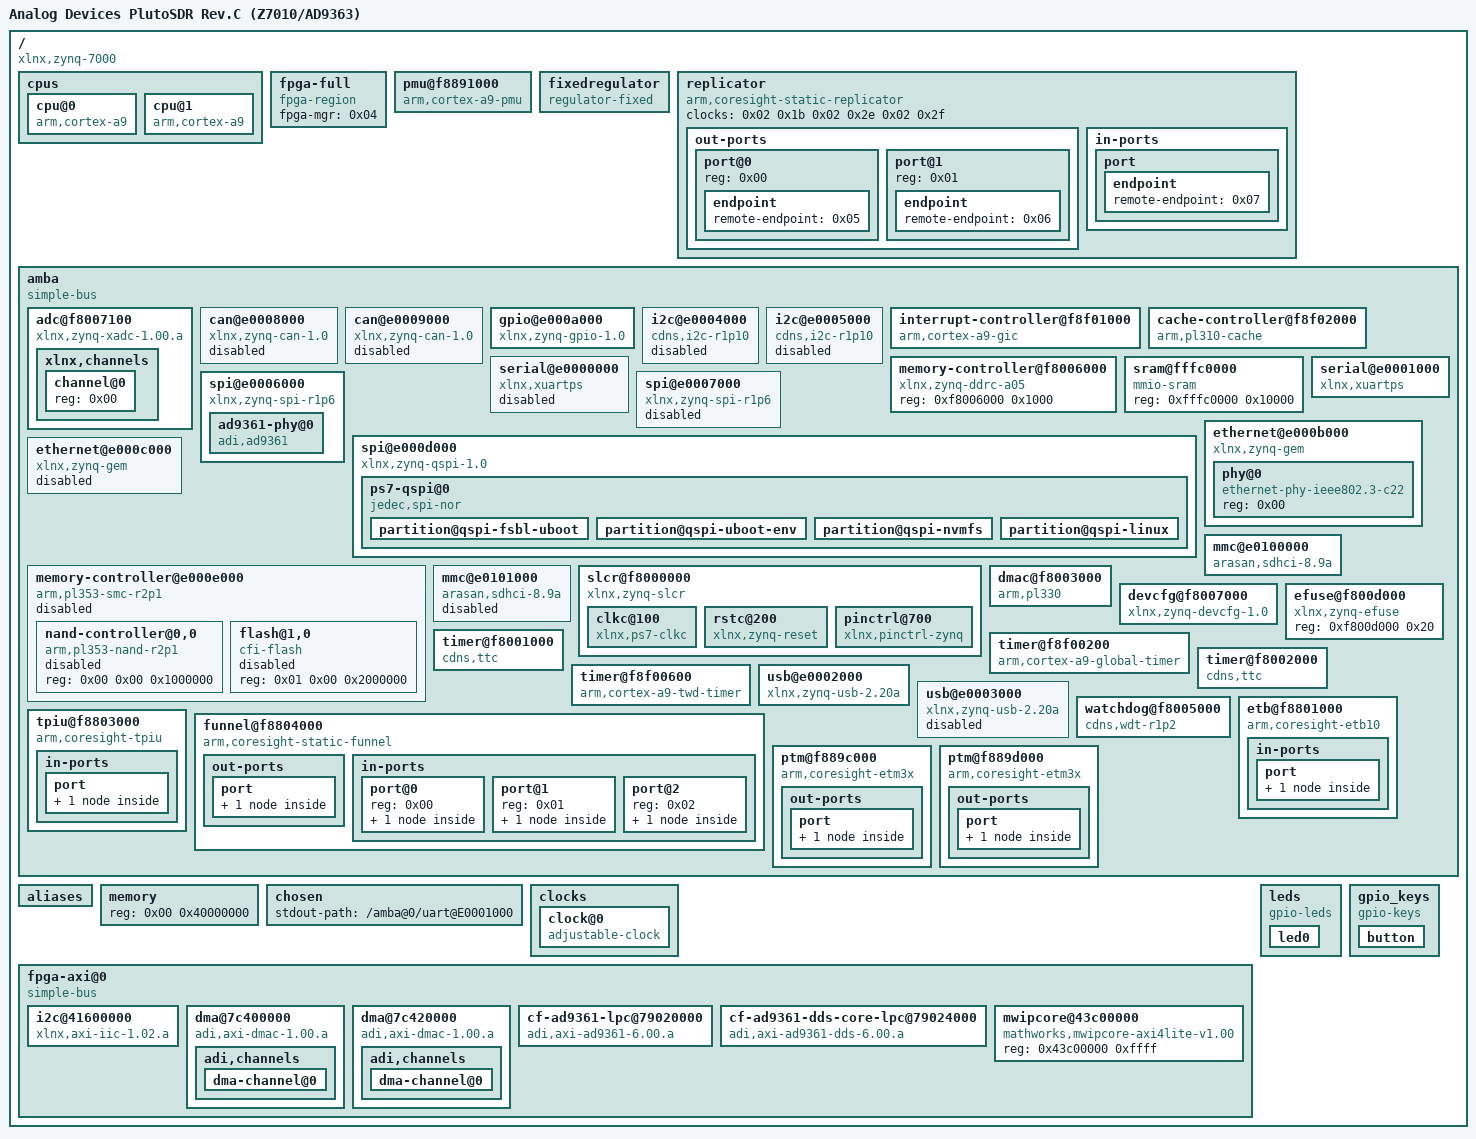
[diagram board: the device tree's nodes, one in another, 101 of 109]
/dts-v1/;

/ {
	#address-cells = <0x01>;
	#size-cells = <0x01>;
	compatible = "xlnx,zynq-7000";
	interrupt-parent = <0x01>;
	model = "Analog Devices PlutoSDR Rev.C (Z7010/AD9363)";

	cpus {
		#address-cells = <0x01>;
		#size-cells = <0x00>;

		cpu@0 {
			compatible = "arm,cortex-a9";
			device_type = "cpu";
			reg = <0x00>;
			clocks = <0x02 0x03>;
			clock-latency = <0x3e8>;
			cpu0-supply = <0x03>;
			operating-points = <0xa2c2b 0xf4240 0x51616 0xf4240>;
			phandle = <0x11>;
		};

		cpu@1 {
			compatible = "arm,cortex-a9";
			device_type = "cpu";
			reg = <0x01>;
			clocks = <0x02 0x03>;
			phandle = <0x13>;
		};
	};

	fpga-full {
		compatible = "fpga-region";
		fpga-mgr = <0x04>;
		#address-cells = <0x01>;
		#size-cells = <0x01>;
		ranges;
		phandle = <0x18>;
	};

	pmu@f8891000 {
		compatible = "arm,cortex-a9-pmu";
		interrupts = <0x00 0x05 0x04 0x00 0x06 0x04>;
		interrupt-parent = <0x01>;
		reg = <0xf8891000 0x1000 0xf8893000 0x1000>;
	};

	fixedregulator {
		compatible = "regulator-fixed";
		regulator-name = "VCCPINT";
		regulator-min-microvolt = <0xf4240>;
		regulator-max-microvolt = <0xf4240>;
		regulator-boot-on;
		regulator-always-on;
		phandle = <0x03>;
	};

	replicator {
		compatible = "arm,coresight-static-replicator";
		clocks = <0x02 0x1b 0x02 0x2e 0x02 0x2f>;
		clock-names = "apb_pclk\0dbg_trc\0dbg_apb";

		out-ports {
			#address-cells = <0x01>;
			#size-cells = <0x00>;

			port@0 {
				reg = <0x00>;

				endpoint {
					remote-endpoint = <0x05>;
					phandle = <0x0d>;
				};
			};

			port@1 {
				reg = <0x01>;

				endpoint {
					remote-endpoint = <0x06>;
					phandle = <0x0c>;
				};
			};
		};

		in-ports {

			port {

				endpoint {
					remote-endpoint = <0x07>;
					phandle = <0x0e>;
				};
			};
		};
	};

	amba {
		u-boot,dm-pre-reloc;
		compatible = "simple-bus";
		#address-cells = <0x01>;
		#size-cells = <0x01>;
		interrupt-parent = <0x01>;
		ranges;
		phandle = <0x19>;

		adc@f8007100 {
			compatible = "xlnx,zynq-xadc-1.00.a";
			reg = <0xf8007100 0x20>;
			interrupts = <0x00 0x07 0x04>;
			interrupt-parent = <0x01>;
			clocks = <0x02 0x0c>;
			phandle = <0x1a>;

			xlnx,channels {
				#address-cells = <0x01>;
				#size-cells = <0x00>;

				channel@0 {
					reg = <0x00>;
				};
			};
		};

		can@e0008000 {
			compatible = "xlnx,zynq-can-1.0";
			status = "disabled";
			clocks = <0x02 0x13 0x02 0x24>;
			clock-names = "can_clk\0pclk";
			reg = <0xe0008000 0x1000>;
			interrupts = <0x00 0x1c 0x04>;
			interrupt-parent = <0x01>;
			tx-fifo-depth = <0x40>;
			rx-fifo-depth = <0x40>;
			phandle = <0x1b>;
		};

		can@e0009000 {
			compatible = "xlnx,zynq-can-1.0";
			status = "disabled";
			clocks = <0x02 0x14 0x02 0x25>;
			clock-names = "can_clk\0pclk";
			reg = <0xe0009000 0x1000>;
			interrupts = <0x00 0x33 0x04>;
			interrupt-parent = <0x01>;
			tx-fifo-depth = <0x40>;
			rx-fifo-depth = <0x40>;
			phandle = <0x1c>;
		};

		gpio@e000a000 {
			compatible = "xlnx,zynq-gpio-1.0";
			#gpio-cells = <0x02>;
			clocks = <0x02 0x2a>;
			gpio-controller;
			interrupt-controller;
			#interrupt-cells = <0x02>;
			interrupt-parent = <0x01>;
			interrupts = <0x00 0x14 0x04>;
			reg = <0xe000a000 0x1000>;
			phandle = <0x09>;
		};

		i2c@e0004000 {
			compatible = "cdns,i2c-r1p10";
			status = "disabled";
			clocks = <0x02 0x26>;
			interrupt-parent = <0x01>;
			interrupts = <0x00 0x19 0x04>;
			reg = <0xe0004000 0x1000>;
			#address-cells = <0x01>;
			#size-cells = <0x00>;
			phandle = <0x1d>;
		};

		i2c@e0005000 {
			compatible = "cdns,i2c-r1p10";
			status = "disabled";
			clocks = <0x02 0x27>;
			interrupt-parent = <0x01>;
			interrupts = <0x00 0x30 0x04>;
			reg = <0xe0005000 0x1000>;
			#address-cells = <0x01>;
			#size-cells = <0x00>;
			phandle = <0x1e>;
		};

		interrupt-controller@f8f01000 {
			compatible = "arm,cortex-a9-gic";
			#interrupt-cells = <0x03>;
			interrupt-controller;
			reg = <0xf8f01000 0x1000 0xf8f00100 0x100>;
			phandle = <0x01>;
		};

		cache-controller@f8f02000 {
			compatible = "arm,pl310-cache";
			reg = <0xf8f02000 0x1000>;
			interrupts = <0x00 0x02 0x04>;
			arm,data-latency = <0x03 0x02 0x02>;
			arm,tag-latency = <0x02 0x02 0x02>;
			cache-unified;
			cache-level = <0x02>;
			phandle = <0x1f>;
		};

		memory-controller@f8006000 {
			compatible = "xlnx,zynq-ddrc-a05";
			reg = <0xf8006000 0x1000>;
			phandle = <0x20>;
		};

		sram@fffc0000 {
			compatible = "mmio-sram";
			reg = <0xfffc0000 0x10000>;
			phandle = <0x21>;
		};

		serial@e0000000 {
			compatible = "xlnx,xuartps\0cdns,uart-r1p8";
			status = "disabled";
			clocks = <0x02 0x17 0x02 0x28>;
			clock-names = "uart_clk\0pclk";
			reg = <0xe0000000 0x1000>;
			interrupts = <0x00 0x1b 0x04>;
			phandle = <0x22>;
		};

		serial@e0001000 {
			compatible = "xlnx,xuartps\0cdns,uart-r1p8";
			status = "okay";
			clocks = <0x02 0x18 0x02 0x29>;
			clock-names = "uart_clk\0pclk";
			reg = <0xe0001000 0x1000>;
			interrupts = <0x00 0x32 0x04>;
			phandle = <0x23>;
		};

		spi@e0006000 {
			compatible = "xlnx,zynq-spi-r1p6";
			reg = <0xe0006000 0x1000>;
			status = "okay";
			interrupt-parent = <0x01>;
			interrupts = <0x00 0x1a 0x04>;
			clocks = <0x02 0x19 0x02 0x22>;
			clock-names = "ref_clk\0pclk";
			#address-cells = <0x01>;
			#size-cells = <0x00>;
			phandle = <0x24>;

			ad9361-phy@0 {
				#address-cells = <0x01>;
				#size-cells = <0x00>;
				#clock-cells = <0x01>;
				compatible = "adi,ad9361";
				reg = <0x00>;
				spi-cpha;
				spi-max-frequency = <0x989680>;
				clocks = <0x08 0x00>;
				clock-names = "ad9364_ext_refclk";
				clock-output-names = "rx_sampl_clk\0tx_sampl_clk";
				adi,digital-interface-tune-skip-mode = <0x00>;
				adi,pp-tx-swap-enable;
				adi,pp-rx-swap-enable;
				adi,rx-frame-pulse-mode-enable;
				adi,lvds-mode-enable;
				adi,lvds-bias-mV = <0x96>;
				adi,lvds-rx-onchip-termination-enable;
				adi,rx-data-delay = <0x04>;
				adi,tx-fb-clock-delay = <0x07>;
				adi,tx-data-delay = <0x09>;
				adi,xo-disable-use-ext-refclk-enable;
				adi,frequency-division-duplex-mode-enable;
				adi,rx-rf-port-input-select = <0x00>;
				adi,rx-rf-port-input-select-lock-enable;
				adi,tx-rf-port-input-select = <0x00>;
				adi,tx-rf-port-input-select-lock-enable;
				adi,tx-attenuation-mdB = <0x2710>;
				adi,tx-lo-powerdown-managed-enable;
				adi,rf-rx-bandwidth-hz = <0x112a880>;
				adi,rf-tx-bandwidth-hz = <0x112a880>;
				adi,rx-synthesizer-frequency-hz = <0x00 0x8f0d1800>;
				adi,tx-synthesizer-frequency-hz = <0x00 0x8f0d1800>;
				adi,rx-path-clock-frequencies = <0x3a980000 0xea60000 0x7530000 0x3a98000 0x1d4c000 0x1d4c000>;
				adi,tx-path-clock-frequencies = <0x3a980000 0x7530000 0x7530000 0x3a98000 0x1d4c000 0x1d4c000>;
				adi,gc-rx1-mode = <0x02>;
				adi,gc-rx2-mode = <0x02>;
				adi,gc-adc-ovr-sample-size = <0x04>;
				adi,gc-adc-small-overload-thresh = <0x2f>;
				adi,gc-adc-large-overload-thresh = <0x3a>;
				adi,gc-lmt-overload-high-thresh = <0x320>;
				adi,gc-lmt-overload-low-thresh = <0x2c0>;
				adi,gc-dec-pow-measurement-duration = <0x2000>;
				adi,gc-low-power-thresh = <0x18>;
				adi,mgc-inc-gain-step = <0x02>;
				adi,mgc-dec-gain-step = <0x02>;
				adi,mgc-split-table-ctrl-inp-gain-mode = <0x00>;
				adi,agc-attack-delay-extra-margin-us = <0x01>;
				adi,agc-outer-thresh-high = <0x05>;
				adi,agc-outer-thresh-high-dec-steps = <0x02>;
				adi,agc-inner-thresh-high = <0x0a>;
				adi,agc-inner-thresh-high-dec-steps = <0x01>;
				adi,agc-inner-thresh-low = <0x0c>;
				adi,agc-inner-thresh-low-inc-steps = <0x01>;
				adi,agc-outer-thresh-low = <0x12>;
				adi,agc-outer-thresh-low-inc-steps = <0x02>;
				adi,agc-adc-small-overload-exceed-counter = <0x0a>;
				adi,agc-adc-large-overload-exceed-counter = <0x0a>;
				adi,agc-adc-large-overload-inc-steps = <0x02>;
				adi,agc-lmt-overload-large-exceed-counter = <0x0a>;
				adi,agc-lmt-overload-small-exceed-counter = <0x0a>;
				adi,agc-lmt-overload-large-inc-steps = <0x02>;
				adi,agc-gain-update-interval-us = <0x3e8>;
				adi,fagc-dec-pow-measurement-duration = <0x40>;
				adi,fagc-lp-thresh-increment-steps = <0x01>;
				adi,fagc-lp-thresh-increment-time = <0x05>;
				adi,fagc-energy-lost-stronger-sig-gain-lock-exit-cnt = <0x08>;
				adi,fagc-final-overrange-count = <0x03>;
				adi,fagc-gain-index-type-after-exit-rx-mode = <0x00>;
				adi,fagc-lmt-final-settling-steps = <0x01>;
				adi,fagc-lock-level = <0x0a>;
				adi,fagc-lock-level-gain-increase-upper-limit = <0x05>;
				adi,fagc-lock-level-lmt-gain-increase-enable;
				adi,fagc-lpf-final-settling-steps = <0x01>;
				adi,fagc-optimized-gain-offset = <0x05>;
				adi,fagc-power-measurement-duration-in-state5 = <0x40>;
				adi,fagc-rst-gla-engergy-lost-goto-optim-gain-enable;
				adi,fagc-rst-gla-engergy-lost-sig-thresh-below-ll = <0x0a>;
				adi,fagc-rst-gla-engergy-lost-sig-thresh-exceeded-enable;
				adi,fagc-rst-gla-if-en-agc-pulled-high-mode = <0x00>;
				adi,fagc-rst-gla-large-adc-overload-enable;
				adi,fagc-rst-gla-large-lmt-overload-enable;
				adi,fagc-rst-gla-stronger-sig-thresh-above-ll = <0x0a>;
				adi,fagc-rst-gla-stronger-sig-thresh-exceeded-enable;
				adi,fagc-state-wait-time-ns = <0x104>;
				adi,fagc-use-last-lock-level-for-set-gain-enable;
				adi,rssi-restart-mode = <0x03>;
				adi,rssi-delay = <0x01>;
				adi,rssi-wait = <0x01>;
				adi,rssi-duration = <0x3e8>;
				adi,ctrl-outs-index = <0x00>;
				adi,ctrl-outs-enable-mask = <0xff>;
				adi,temp-sense-measurement-interval-ms = <0x3e8>;
				adi,temp-sense-offset-signed = <0xce>;
				adi,temp-sense-periodic-measurement-enable;
				adi,aux-dac-manual-mode-enable;
				adi,aux-dac1-default-value-mV = <0x00>;
				adi,aux-dac1-rx-delay-us = <0x00>;
				adi,aux-dac1-tx-delay-us = <0x00>;
				adi,aux-dac2-default-value-mV = <0x00>;
				adi,aux-dac2-rx-delay-us = <0x00>;
				adi,aux-dac2-tx-delay-us = <0x00>;
				en_agc-gpios = <0x09 0x42 0x00>;
				reset-gpios = <0x09 0x43 0x00>;
				adi,2rx-2tx-mode-enable;
				phandle = <0x16>;
			};
		};

		spi@e0007000 {
			compatible = "xlnx,zynq-spi-r1p6";
			reg = <0xe0007000 0x1000>;
			status = "disabled";
			interrupt-parent = <0x01>;
			interrupts = <0x00 0x31 0x04>;
			clocks = <0x02 0x1a 0x02 0x23>;
			clock-names = "ref_clk\0pclk";
			#address-cells = <0x01>;
			#size-cells = <0x00>;
			phandle = <0x25>;
		};

		spi@e000d000 {
			clock-names = "ref_clk\0pclk";
			clocks = <0x02 0x0a 0x02 0x2b>;
			compatible = "xlnx,zynq-qspi-1.0";
			status = "okay";
			interrupt-parent = <0x01>;
			interrupts = <0x00 0x13 0x04>;
			reg = <0xe000d000 0x1000>;
			#address-cells = <0x01>;
			#size-cells = <0x00>;
			is-dual = <0x00>;
			num-cs = <0x01>;
			spi-nor-locking-disable;
			phandle = <0x26>;

			ps7-qspi@0 {
				#address-cells = <0x01>;
				#size-cells = <0x01>;
				spi-tx-bus-width = <0x01>;
				spi-rx-bus-width = <0x04>;
				compatible = "jedec,spi-nor";
				reg = <0x00>;
				spi-max-frequency = <0x2faf080>;
				phandle = <0x27>;

				partition@qspi-fsbl-uboot {
					label = "qspi-fsbl-uboot";
					reg = <0x00 0x100000>;
				};

				partition@qspi-uboot-env {
					label = "qspi-uboot-env";
					reg = <0x100000 0x20000>;
				};

				partition@qspi-nvmfs {
					label = "qspi-nvmfs";
					reg = <0x120000 0xe0000>;
				};

				partition@qspi-linux {
					label = "qspi-linux";
					reg = <0x200000 0xe00000>;
				};
			};
		};

		ethernet@e000b000 {
			compatible = "xlnx,zynq-gem\0cdns,zynq-gem\0cdns,gem";
			reg = <0xe000b000 0x1000>;
			status = "okay";
			interrupts = <0x00 0x16 0x04>;
			clocks = <0x02 0x1e 0x02 0x1e 0x02 0x0d>;
			clock-names = "pclk\0hclk\0tx_clk";
			#address-cells = <0x01>;
			#size-cells = <0x00>;
			phy-mode = "rgmii-id";
			phy-handle = <0x0a>;
			phandle = <0x28>;

			phy@0 {
				reg = <0x00>;
				compatible = "ethernet-phy-ieee802.3-c22";
				phandle = <0x0a>;
			};
		};

		ethernet@e000c000 {
			compatible = "xlnx,zynq-gem\0cdns,zynq-gem\0cdns,gem";
			reg = <0xe000c000 0x1000>;
			status = "disabled";
			interrupts = <0x00 0x2d 0x04>;
			clocks = <0x02 0x1f 0x02 0x1f 0x02 0x0e>;
			clock-names = "pclk\0hclk\0tx_clk";
			#address-cells = <0x01>;
			#size-cells = <0x00>;
			phandle = <0x29>;
		};

		memory-controller@e000e000 {
			compatible = "arm,pl353-smc-r2p1\0arm,primecell";
			reg = <0xe000e000 0x1000>;
			status = "disabled";
			clock-names = "memclk\0apb_pclk";
			clocks = <0x02 0x0b 0x02 0x2c>;
			ranges = <0x00 0x00 0xe1000000 0x1000000 0x01 0x00 0xe2000000 0x2000000 0x02 0x00 0xe4000000 0x2000000>;
			#address-cells = <0x02>;
			#size-cells = <0x01>;
			interrupt-parent = <0x01>;
			interrupts = <0x00 0x12 0x04>;
			phandle = <0x2a>;

			nand-controller@0,0 {
				compatible = "arm,pl353-nand-r2p1";
				reg = <0x00 0x00 0x1000000>;
				status = "disabled";
				#address-cells = <0x01>;
				#size-cells = <0x00>;
				phandle = <0x2b>;
			};

			flash@1,0 {
				status = "disabled";
				compatible = "cfi-flash";
				reg = <0x01 0x00 0x2000000>;
				#address-cells = <0x01>;
				#size-cells = <0x01>;
				phandle = <0x2c>;
			};
		};

		mmc@e0100000 {
			compatible = "arasan,sdhci-8.9a";
			status = "okay";
			clock-names = "clk_xin\0clk_ahb";
			clocks = <0x02 0x15 0x02 0x20>;
			interrupt-parent = <0x01>;
			interrupts = <0x00 0x18 0x04>;
			reg = <0xe0100000 0x1000>;
			xlnx,has-cd = <0x00>;
			xlnx,has-power = <0x00>;
			xlnx,has-wp = <0x00>;
			phandle = <0x2d>;
		};

		mmc@e0101000 {
			compatible = "arasan,sdhci-8.9a";
			status = "disabled";
			clock-names = "clk_xin\0clk_ahb";
			clocks = <0x02 0x16 0x02 0x21>;
			interrupt-parent = <0x01>;
			interrupts = <0x00 0x2f 0x04>;
			reg = <0xe0101000 0x1000>;
			phandle = <0x2e>;
		};

		slcr@f8000000 {
			u-boot,dm-pre-reloc;
			#address-cells = <0x01>;
			#size-cells = <0x01>;
			compatible = "xlnx,zynq-slcr\0syscon\0simple-mfd";
			reg = <0xf8000000 0x1000>;
			ranges;
			phandle = <0x0b>;

			clkc@100 {
				u-boot,dm-pre-reloc;
				#clock-cells = <0x01>;
				compatible = "xlnx,ps7-clkc";
				fclk-enable = <0x0f>;
				clock-output-names = "armpll\0ddrpll\0iopll\0cpu_6or4x\0cpu_3or2x\0cpu_2x\0cpu_1x\0ddr2x\0ddr3x\0dci\0lqspi\0smc\0pcap\0gem0\0gem1\0fclk0\0fclk1\0fclk2\0fclk3\0can0\0can1\0sdio0\0sdio1\0uart0\0uart1\0spi0\0spi1\0dma\0usb0_aper\0usb1_aper\0gem0_aper\0gem1_aper\0sdio0_aper\0sdio1_aper\0spi0_aper\0spi1_aper\0can0_aper\0can1_aper\0i2c0_aper\0i2c1_aper\0uart0_aper\0uart1_aper\0gpio_aper\0lqspi_aper\0smc_aper\0swdt\0dbg_trc\0dbg_apb";
				reg = <0x100 0x100>;
				ps-clk-frequency = <0x1fca055>;
				phandle = <0x02>;
			};

			rstc@200 {
				compatible = "xlnx,zynq-reset";
				reg = <0x200 0x48>;
				#reset-cells = <0x01>;
				syscon = <0x0b>;
				phandle = <0x2f>;
			};

			pinctrl@700 {
				compatible = "xlnx,pinctrl-zynq";
				reg = <0x700 0x200>;
				syscon = <0x0b>;
				phandle = <0x30>;
			};
		};

		dmac@f8003000 {
			compatible = "arm,pl330\0arm,primecell";
			reg = <0xf8003000 0x1000>;
			interrupt-parent = <0x01>;
			interrupt-names = "abort\0dma0\0dma1\0dma2\0dma3\0dma4\0dma5\0dma6\0dma7";
			interrupts = <0x00 0x0d 0x04 0x00 0x0e 0x04 0x00 0x0f 0x04 0x00 0x10 0x04 0x00 0x11 0x04 0x00 0x28 0x04 0x00 0x29 0x04 0x00 0x2a 0x04 0x00 0x2b 0x04>;
			#dma-cells = <0x01>;
			#dma-channels = <0x08>;
			#dma-requests = <0x04>;
			clocks = <0x02 0x1b>;
			clock-names = "apb_pclk";
			phandle = <0x31>;
		};

		devcfg@f8007000 {
			compatible = "xlnx,zynq-devcfg-1.0";
			interrupt-parent = <0x01>;
			interrupts = <0x00 0x08 0x04>;
			reg = <0xf8007000 0x100>;
			clocks = <0x02 0x0c 0x02 0x0f 0x02 0x10 0x02 0x11 0x02 0x12>;
			clock-names = "ref_clk\0fclk0\0fclk1\0fclk2\0fclk3";
			syscon = <0x0b>;
			phandle = <0x04>;
		};

		efuse@f800d000 {
			compatible = "xlnx,zynq-efuse";
			reg = <0xf800d000 0x20>;
			phandle = <0x32>;
		};

		timer@f8f00200 {
			compatible = "arm,cortex-a9-global-timer";
			reg = <0xf8f00200 0x20>;
			interrupts = <0x01 0x0b 0x301>;
			interrupt-parent = <0x01>;
			clocks = <0x02 0x04>;
			phandle = <0x33>;
		};

		timer@f8001000 {
			interrupt-parent = <0x01>;
			interrupts = <0x00 0x0a 0x04 0x00 0x0b 0x04 0x00 0x0c 0x04>;
			compatible = "cdns,ttc";
			clocks = <0x02 0x06>;
			reg = <0xf8001000 0x1000>;
			phandle = <0x34>;
		};

		timer@f8002000 {
			interrupt-parent = <0x01>;
			interrupts = <0x00 0x25 0x04 0x00 0x26 0x04 0x00 0x27 0x04>;
			compatible = "cdns,ttc";
			clocks = <0x02 0x06>;
			reg = <0xf8002000 0x1000>;
			phandle = <0x35>;
		};

		timer@f8f00600 {
			interrupt-parent = <0x01>;
			interrupts = <0x01 0x0d 0x301>;
			compatible = "arm,cortex-a9-twd-timer";
			reg = <0xf8f00600 0x20>;
			clocks = <0x02 0x04>;
			phandle = <0x36>;
		};

		usb@e0002000 {
			compatible = "xlnx,zynq-usb-2.20a\0chipidea,usb2";
			status = "okay";
			clocks = <0x02 0x1c>;
			interrupt-parent = <0x01>;
			interrupts = <0x00 0x15 0x04>;
			reg = <0xe0002000 0x1000>;
			phy_type = "ulpi";
			dr_mode = "otg";
			xlnx,phy-reset-gpio = <0x09 0x2e 0x00>;
			phandle = <0x37>;
		};

		usb@e0003000 {
			compatible = "xlnx,zynq-usb-2.20a\0chipidea,usb2";
			status = "disabled";
			clocks = <0x02 0x1d>;
			interrupt-parent = <0x01>;
			interrupts = <0x00 0x2c 0x04>;
			reg = <0xe0003000 0x1000>;
			phy_type = "ulpi";
			phandle = <0x38>;
		};

		watchdog@f8005000 {
			clocks = <0x02 0x2d>;
			compatible = "cdns,wdt-r1p2";
			interrupt-parent = <0x01>;
			interrupts = <0x00 0x09 0x01>;
			reg = <0xf8005000 0x1000>;
			timeout-sec = <0x0a>;
			status = "okay";
			reset-on-timeout;
			phandle = <0x39>;
		};

		etb@f8801000 {
			compatible = "arm,coresight-etb10\0arm,primecell";
			reg = <0xf8801000 0x1000>;
			clocks = <0x02 0x1b 0x02 0x2e 0x02 0x2f>;
			clock-names = "apb_pclk\0dbg_trc\0dbg_apb";

			in-ports {

				port {

					endpoint {
						remote-endpoint = <0x0c>;
						phandle = <0x06>;
					};
				};
			};
		};

		tpiu@f8803000 {
			compatible = "arm,coresight-tpiu\0arm,primecell";
			reg = <0xf8803000 0x1000>;
			clocks = <0x02 0x1b 0x02 0x2e 0x02 0x2f>;
			clock-names = "apb_pclk\0dbg_trc\0dbg_apb";

			in-ports {

				port {

					endpoint {
						remote-endpoint = <0x0d>;
						phandle = <0x05>;
					};
				};
			};
		};

		funnel@f8804000 {
			compatible = "arm,coresight-static-funnel\0arm,primecell";
			reg = <0xf8804000 0x1000>;
			clocks = <0x02 0x1b 0x02 0x2e 0x02 0x2f>;
			clock-names = "apb_pclk\0dbg_trc\0dbg_apb";

			out-ports {

				port {

					endpoint {
						remote-endpoint = <0x0e>;
						phandle = <0x07>;
					};
				};
			};

			in-ports {
				#address-cells = <0x01>;
				#size-cells = <0x00>;

				port@0 {
					reg = <0x00>;

					endpoint {
						remote-endpoint = <0x0f>;
						phandle = <0x12>;
					};
				};

				port@1 {
					reg = <0x01>;

					endpoint {
						remote-endpoint = <0x10>;
						phandle = <0x14>;
					};
				};

				port@2 {
					reg = <0x02>;

					endpoint {
						phandle = <0x3a>;
					};
				};
			};
		};

		ptm@f889c000 {
			compatible = "arm,coresight-etm3x\0arm,primecell";
			reg = <0xf889c000 0x1000>;
			clocks = <0x02 0x1b 0x02 0x2e 0x02 0x2f>;
			clock-names = "apb_pclk\0dbg_trc\0dbg_apb";
			cpu = <0x11>;

			out-ports {

				port {

					endpoint {
						remote-endpoint = <0x12>;
						phandle = <0x0f>;
					};
				};
			};
		};

		ptm@f889d000 {
			compatible = "arm,coresight-etm3x\0arm,primecell";
			reg = <0xf889d000 0x1000>;
			clocks = <0x02 0x1b 0x02 0x2e 0x02 0x2f>;
			clock-names = "apb_pclk\0dbg_trc\0dbg_apb";
			cpu = <0x13>;

			out-ports {

				port {

					endpoint {
						remote-endpoint = <0x14>;
						phandle = <0x10>;
					};
				};
			};
		};
	};

	aliases {
		ethernet0 = "/axi/ethernet@e000b000";
		serial0 = "/axi/serial@e0001000";
		phandle = <0x3b>;
	};

	memory {
		device_type = "memory";
		reg = <0x00 0x40000000>;
	};

	chosen {
		stdout-path = "/amba@0/uart@E0001000";
	};

	clocks {

		clock@0 {
			#clock-cells = <0x00>;
			compatible = "adjustable-clock";
			clock-frequency = <0x2625a00>;
			clock-accuracy = <0x1f4>;
			clock-output-names = "ad9364_ext_refclk";
			phandle = <0x08>;
		};
	};

	fpga-axi@0 {
		compatible = "simple-bus";
		#address-cells = <0x01>;
		#size-cells = <0x01>;
		ranges;
		phandle = <0x3c>;

		i2c@41600000 {
			compatible = "xlnx,axi-iic-1.02.a\0xlnx,xps-iic-2.00.a";
			reg = <0x41600000 0x10000>;
			interrupt-parent = <0x01>;
			interrupts = <0x00 0x3b 0x04>;
			clocks = <0x02 0x0f>;
			clock-names = "pclk";
			#address-cells = <0x01>;
			#size-cells = <0x00>;
			phandle = <0x3d>;
		};

		dma@7c400000 {
			compatible = "adi,axi-dmac-1.00.a";
			reg = <0x7c400000 0x1000>;
			#dma-cells = <0x01>;
			interrupts = <0x00 0x39 0x04>;
			clocks = <0x02 0x10>;
			phandle = <0x15>;

			adi,channels {
				#size-cells = <0x00>;
				#address-cells = <0x01>;

				dma-channel@0 {
					reg = <0x00>;
					adi,source-bus-width = <0x20>;
					adi,source-bus-type = <0x02>;
					adi,destination-bus-width = <0x40>;
					adi,destination-bus-type = <0x00>;
				};
			};
		};

		dma@7c420000 {
			compatible = "adi,axi-dmac-1.00.a";
			reg = <0x7c420000 0x1000>;
			#dma-cells = <0x01>;
			interrupts = <0x00 0x38 0x04>;
			clocks = <0x02 0x10>;
			phandle = <0x17>;

			adi,channels {
				#size-cells = <0x00>;
				#address-cells = <0x01>;

				dma-channel@0 {
					reg = <0x00>;
					adi,source-bus-width = <0x40>;
					adi,source-bus-type = <0x00>;
					adi,destination-bus-width = <0x20>;
					adi,destination-bus-type = <0x02>;
				};
			};
		};

		cf-ad9361-lpc@79020000 {
			compatible = "adi,axi-ad9361-6.00.a";
			reg = <0x79020000 0x6000>;
			dmas = <0x15 0x00>;
			dma-names = "rx";
			spibus-connected = <0x16>;
			adi,axi-decimation-core-available;
			phandle = <0x3e>;
		};

		cf-ad9361-dds-core-lpc@79024000 {
			compatible = "adi,axi-ad9361-dds-6.00.a";
			reg = <0x79024000 0x1000>;
			clocks = <0x16 0x0d>;
			clock-names = "sampl_clk";
			dmas = <0x17 0x00>;
			dma-names = "tx";
			adi,axi-interpolation-core-available;
			adi,axi-dds-default-scale = <0x00>;
			phandle = <0x3f>;
		};

		mwipcore@43c00000 {
			compatible = "mathworks,mwipcore-axi4lite-v1.00";
			reg = <0x43c00000 0xffff>;
		};
	};

	leds {
		compatible = "gpio-leds";

		led0 {
			label = "led0:yellow";
			gpios = <0x09 0x00 0x00>;
			linux,default-trigger = "heartbeat";
		};
	};

	gpio_keys {
		compatible = "gpio-keys";
		#address-cells = <0x01>;
		#size-cells = <0x00>;

		button {
			interrupt-parent = <0x09>;
			interrupts = <0x0a 0x02>;
			label = "Button";
			linux,code = <0x100>;
		};
	};

	__symbols__ {
		cpu0 = "/cpus/cpu@0";
		cpu1 = "/cpus/cpu@1";
		fpga_full = "/fpga-full";
		regulator_vccpint = "/fixedregulator";
		replicator_out_port0 = "/replicator/out-ports/port@0/endpoint";
		replicator_out_port1 = "/replicator/out-ports/port@1/endpoint";
		replicator_in_port0 = "/replicator/in-ports/port/endpoint";
		amba = "/axi";
		adc = "/axi/adc@f8007100";
		can0 = "/axi/can@e0008000";
		can1 = "/axi/can@e0009000";
		gpio0 = "/axi/gpio@e000a000";
		i2c0 = "/axi/i2c@e0004000";
		i2c1 = "/axi/i2c@e0005000";
		intc = "/axi/interrupt-controller@f8f01000";
		L2 = "/axi/cache-controller@f8f02000";
		mc = "/axi/memory-controller@f8006000";
		ocm = "/axi/sram@fffc0000";
		uart0 = "/axi/serial@e0000000";
		uart1 = "/axi/serial@e0001000";
		spi0 = "/axi/spi@e0006000";
		adc0_ad9364 = "/axi/spi@e0006000/ad9361-phy@0";
		spi1 = "/axi/spi@e0007000";
		qspi = "/axi/spi@e000d000";
		primary_flash = "/axi/spi@e000d000/ps7-qspi@0";
		gem0 = "/axi/ethernet@e000b000";
		phy0 = "/axi/ethernet@e000b000/phy@0";
		gem1 = "/axi/ethernet@e000c000";
		smcc = "/axi/memory-controller@e000e000";
		nfc0 = "/axi/memory-controller@e000e000/nand-controller@0,0";
		nor0 = "/axi/memory-controller@e000e000/flash@1,0";
		sdhci0 = "/axi/mmc@e0100000";
		sdhci1 = "/axi/mmc@e0101000";
		slcr = "/axi/slcr@f8000000";
		clkc = "/axi/slcr@f8000000/clkc@100";
		rstc = "/axi/slcr@f8000000/rstc@200";
		pinctrl0 = "/axi/slcr@f8000000/pinctrl@700";
		dmac_s = "/axi/dmac@f8003000";
		devcfg = "/axi/devcfg@f8007000";
		efuse = "/axi/efuse@f800d000";
		global_timer = "/axi/timer@f8f00200";
		ttc0 = "/axi/timer@f8001000";
		ttc1 = "/axi/timer@f8002000";
		scutimer = "/axi/timer@f8f00600";
		usb0 = "/axi/usb@e0002000";
		usb1 = "/axi/usb@e0003000";
		watchdog0 = "/axi/watchdog@f8005000";
		etb_in_port = "/axi/etb@f8801000/in-ports/port/endpoint";
		tpiu_in_port = "/axi/tpiu@f8803000/in-ports/port/endpoint";
		funnel_out_port = "/axi/funnel@f8804000/out-ports/port/endpoint";
		funnel0_in_port0 = "/axi/funnel@f8804000/in-ports/port@0/endpoint";
		funnel0_in_port1 = "/axi/funnel@f8804000/in-ports/port@1/endpoint";
		funnel0_in_port2 = "/axi/funnel@f8804000/in-ports/port@2/endpoint";
		ptm0_out_port = "/axi/ptm@f889c000/out-ports/port/endpoint";
		ptm1_out_port = "/axi/ptm@f889d000/out-ports/port/endpoint";
		aliases = "/aliases";
		ad9364_clkin = "/clocks/clock@0";
		fpga_axi = "/fpga-axi@0";
		axi_i2c0 = "/fpga-axi@0/i2c@41600000";
		rx_dma = "/fpga-axi@0/dma@7c400000";
		tx_dma = "/fpga-axi@0/dma@7c420000";
		cf_ad9364_adc_core_0 = "/fpga-axi@0/cf-ad9361-lpc@79020000";
		cf_ad9364_dac_core_0 = "/fpga-axi@0/cf-ad9361-dds-core-lpc@79024000";
	};
};
